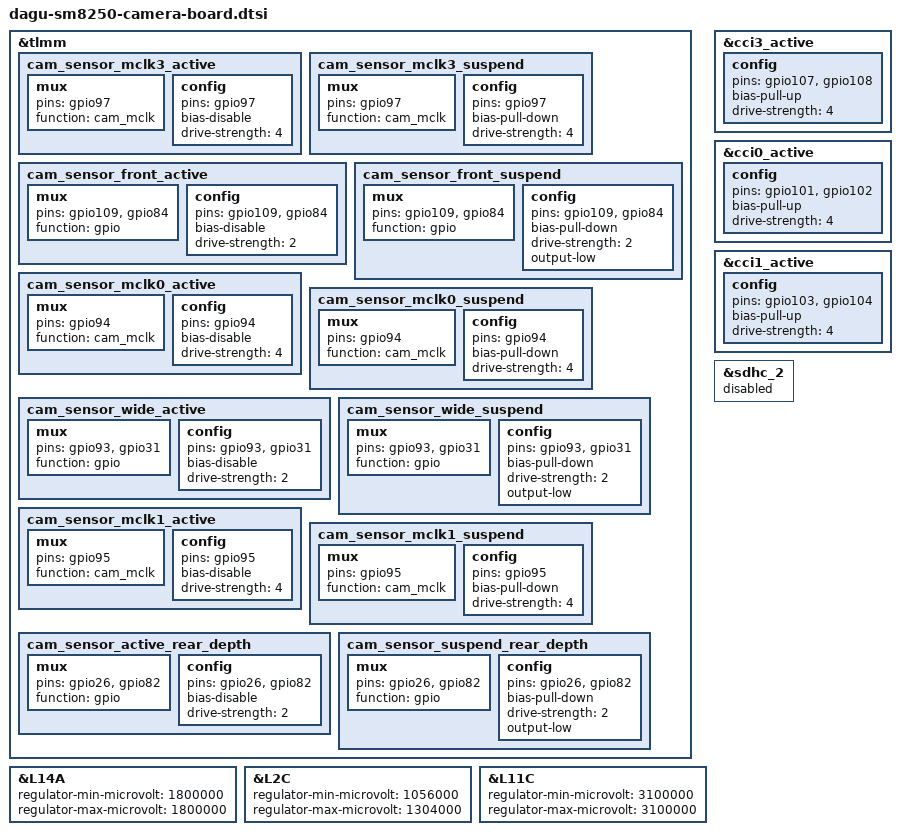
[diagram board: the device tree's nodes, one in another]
&tlmm {
	cam_sensor_mclk3_active: cam_sensor_mclk3_active {
		/* FRONT MCLK0 */
		mux {
			pins = "gpio97";
			function = "cam_mclk";
		};

		config {
			pins = "gpio97";
			bias-disable; /* No PULL */
			drive-strength = <4>; /* 4 MA */
		};
	};
	cam_sensor_mclk3_suspend: cam_sensor_mclk3_suspend {
		/* FRONT MCLK0 */
		mux {
			pins = "gpio97";
			function = "cam_mclk";
		};

		config {
			pins = "gpio97";
			bias-pull-down; /* PULL DOWN */
			drive-strength = <4>; /* 4 MA */
		};
	};
	cam_sensor_front_active: cam_sensor_front_active {
		/* FRONT RESET AVDD */
		mux {
			pins = "gpio109", "gpio84";
			function = "gpio";
		};

		config {
			pins = "gpio109", "gpio84";
			bias-disable; /* No PULL */
			drive-strength = <2>; /* 2 MA */
		};
	};
	cam_sensor_front_suspend: cam_sensor_front_suspend {
		mux {
			pins = "gpio109", "gpio84";
			function = "gpio";
		};

		config {
			pins = "gpio109", "gpio84";
			bias-pull-down; /* PULL DOWN */
			drive-strength = <2>; /* 2 MA */
			output-low;
		};
	};

	cam_sensor_mclk0_active: cam_sensor_mclk0_active {
		/* WIDE MCLK1 */
		mux {
			pins = "gpio94";
			function = "cam_mclk";
		};

		config {
			pins = "gpio94";
			bias-disable; /* No PULL */
			drive-strength = <4>; /* 4 MA */
		};
	};
	cam_sensor_mclk0_suspend: cam_sensor_mclk0_suspend {
		/* WIDE MCLK1 */
		mux {
			pins = "gpio94";
			function = "cam_mclk";
		};

		config {
			pins = "gpio94";
			bias-pull-down; /* PULL DOWN */
			drive-strength = <4>; /* 4 MA */
		};
	};
	cam_sensor_wide_active: cam_sensor_wide_active {
		/* WIDE RESET AVDD*/
		mux {
			pins = "gpio93", "gpio31";
			function = "gpio";
		};

		config {
			pins = "gpio93", "gpio31";
			bias-disable; /* No PULL */
			drive-strength = <2>; /* 2 MA */
		};
	};
	cam_sensor_wide_suspend: cam_sensor_wide_suspend {
		mux {
			pins = "gpio93", "gpio31";
			function = "gpio";
		};

		config {
			pins = "gpio93", "gpio31";
			bias-pull-down; /* PULL DOWN */
			drive-strength = <2>; /* 2 MA */
			output-low;
		};
	};

	cam_sensor_mclk1_active: cam_sensor_mclk1_active {
		/* DEPTH MCLK2 */
		mux {
			pins = "gpio95";
			function = "cam_mclk";
		};

		config {
			pins = "gpio95";
			bias-disable; /* No PULL */
			drive-strength = <4>; /* 4 MA */
		};
	};
	cam_sensor_mclk1_suspend: cam_sensor_mclk1_suspend {
		/* DEPTH MCLK2 */
		mux {
			pins = "gpio95";
			function = "cam_mclk";
		};

		config {
			pins = "gpio95";
			bias-pull-down; /* PULL DOWN */
			drive-strength = <4>; /* 4 MA */
		};
	};
	cam_sensor_active_rear_depth:cam_sensor_active_rear_depth {
		/* DEPTH RESET AVDD */
		mux {
			pins = "gpio26", "gpio82";
			function = "gpio";
		};

		config {
			pins = "gpio26", "gpio82";
			bias-disable; /* No PULL */
			drive-strength = <2>; /* 2 MA */
		};
	};
	cam_sensor_suspend_rear_depth:cam_sensor_suspend_rear_depth {
		mux {
			pins = "gpio26", "gpio82";
			function = "gpio";
		};

		config {
			pins = "gpio26", "gpio82";
			bias-pull-down; /* PULL DOWN */
			drive-strength = <2>; /* 2 MA */
			output-low;
		};
	};
};

&L14A {
	regulator-min-microvolt = <1800000>;
	regulator-max-microvolt = <1800000>;
};
&L2C {
	regulator-min-microvolt = <1056000>;
	regulator-max-microvolt = <1304000>;
};
&L11C {
	regulator-min-microvolt = <3100000>;
	regulator-max-microvolt = <3100000>;
};

&cci3_active {
    config {
        pins = "gpio107","gpio108";
        bias-pull-up; /* PULL UP*/
        drive-strength = <4>; /* 4 MA */
    };
};

&cci0_active {
    config {
        pins = "gpio101","gpio102";
        bias-pull-up; /* PULL UP*/
        drive-strength = <4>; /* 4 MA */
    };
};

&cci1_active {
    config {
        pins = "gpio103","gpio104";
        bias-pull-up; /* PULL UP*/
        drive-strength = <4>; /* 4 MA */
    };
};

&sdhc_2 {
	status = "disabled";
};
